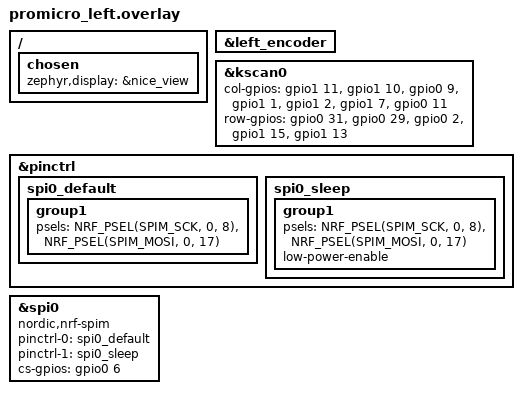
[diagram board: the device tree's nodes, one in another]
// promicro_left.overlay

#include "promicro.dtsi"
#include <dt-bindings/led/led.h>

&left_encoder {
	status = "okay";
};

&kscan0 {
    col-gpios
	= <&gpio1 11  GPIO_ACTIVE_HIGH>  
	, <&gpio1 10  GPIO_ACTIVE_HIGH>  
        , <&gpio0 9  GPIO_ACTIVE_HIGH>  
	, <&gpio1 1  GPIO_ACTIVE_HIGH>  
	, <&gpio1 2  GPIO_ACTIVE_HIGH>  
	, <&gpio1 7  GPIO_ACTIVE_HIGH>
	, <&gpio0 11 GPIO_ACTIVE_HIGH>
	;

     row-gpios
         = <&gpio0 31 (GPIO_ACTIVE_HIGH | GPIO_PULL_DOWN)>  
	 , <&gpio0 29  (GPIO_ACTIVE_HIGH | GPIO_PULL_DOWN)>  
         , <&gpio0 2  (GPIO_ACTIVE_HIGH | GPIO_PULL_DOWN)>  
	 , <&gpio1 15  (GPIO_ACTIVE_HIGH | GPIO_PULL_DOWN)> 
         , <&gpio1 13  (GPIO_ACTIVE_HIGH | GPIO_PULL_DOWN)>  
         ;
};

&pinctrl {
    spi0_default: spi0_default {
        group1 {
            psels = <NRF_PSEL(SPIM_SCK, 0, 8)>,
                <NRF_PSEL(SPIM_MOSI, 0, 17)>;
        };
    };
    spi0_sleep: spi0_sleep {
        group1 {
            psels = <NRF_PSEL(SPIM_SCK, 0, 8)>,
                <NRF_PSEL(SPIM_MOSI, 0, 17)>;
            low-power-enable;
        };
    };
};

nice_view_spi: &spi0 {
    compatible = "nordic,nrf-spim";
    pinctrl-0 = <&spi0_default>;
    pinctrl-1 = <&spi0_sleep>;
    pinctrl-names = "default", "sleep";
    cs-gpios = <&gpio0 6 GPIO_ACTIVE_HIGH>;
};

/ {
    chosen {
        zephyr,display = &nice_view;
    };
};
